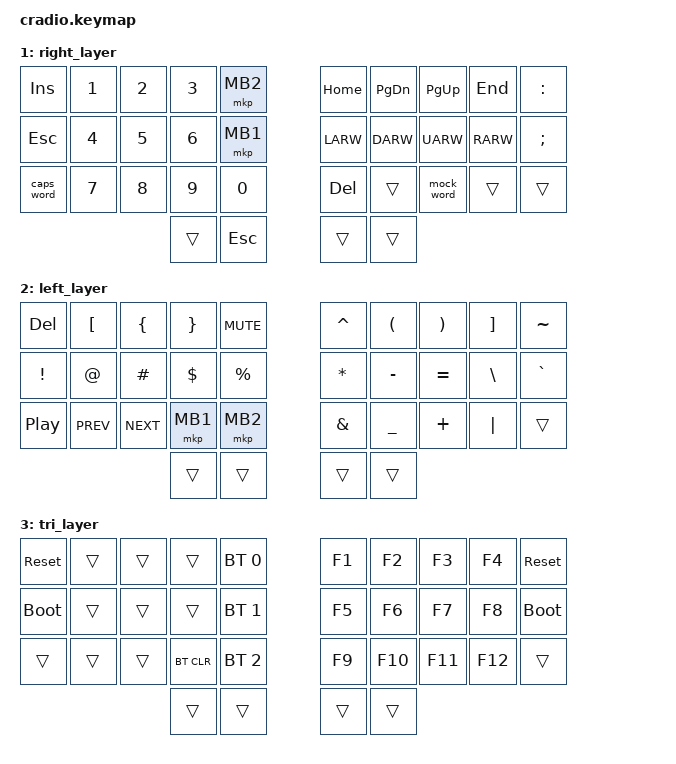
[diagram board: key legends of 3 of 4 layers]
// Copyright (c) 2022 The ZMK Contributors
// SPDX-License-Identifier: MIT

#include <behaviors.dtsi>
#include <dt-bindings/zmk/keys.h>
#include <dt-bindings/zmk/bt.h>
#include <dt-bindings/zmk/pointing.h>

// Home row mods macro
#define HRML(k1,k2,k3,k4) &ht LGUI k1  &ht LALT k2  &ht LCTRL k3  &ht LSHFT k4
#define HRMR(k1,k2,k3,k4) &ht RSHFT k1  &ht RCTRL k2  &ht RALT k3  &ht RGUI k4

// Combo macro
#define COMBO(NAME, BINDINGS, KEYPOS) \
  combo_##NAME { \
    timeout-ms = <50>; \
    require-prior-idle-ms = <150>; \
    bindings = <BINDINGS>; \
    key-positions = <KEYPOS>; \
    layers = <0>; \
  };

/ {
      combos {
        compatible = "zmk,combos";
        COMBO(Z, &kp Z, 0 1)
        COMBO(Q, &kp Q, 1 2)
        COMBO(capsword, &caps_word, 1 3)

        COMBO(tmux, &kp LC(B), 11 13)
        COMBO(tmux2, &kp LC(B), 16 18)
        COMBO(copy, &kp LG(C), 21 22)
        COMBO(paste, &kp LG(V), 20 21)
        COMBO(undo, &kp LG(Z), 26 27)
        COMBO(cut, &kp LG(X), 27 28)
        COMBO(backslash, &kp BSLH, 28 29)
        COMBO(bspc, &kp BSPC, 26 28)

        COMBO(esckey, &kp ESC, 2 3)
        COMBO(esckey2, &kp ESC, 6 7)
        COMBO(tabkey, &kp TAB, 12 13)
        COMBO(tabkey2, &kp TAB, 16 17)
        COMBO(space, &kp SPACE, 22 23)
        COMBO(enter, &kp RET, 21 23)
        
        COMBO(one, &kp LC(N1), 0 10)
        COMBO(two, &kp LC(N2), 1 11)
        COMBO(three, &kp LC(N3), 2 12)
        COMBO(four, &kp LC(N4), 3 13)
        COMBO(five, &kp LC(N5), 4 14)
        COMBO(six, &kp LC(N6), 5 15)
        COMBO(seven, &kp LC(N7), 6 16)
        COMBO(eight, &kp LC(N8), 7 17)
        COMBO(nine, &kp LC(N9), 8 18)
        COMBO(zero, &kp LC(N0), 9 19)

        // COMBO(ctrlL, &kp LC(LEFT), 10 11)
        // COMBO(ctrlR, &kp LC(RIGHT), 11 12)
        // COMBO(ctrl1, &kp LC(N1), 4 5)
        // COMBO(ctrl2, &kp LC(N2), 14 15)
        // COMBO(ctrl3, &kp LC(N3), 24 25)
        // COMBO(ctrl4, &kp LC(N4), 6 7)
        // COMBO(ctrl5, &kp LC(N5), 16 17)
        // COMBO(ctrl6, &kp LC(N6), 26 27)

    };

    behaviors {
        ht: hold_tap {
            label = "hold_tap";
            compatible = "zmk,behavior-hold-tap";
            #binding-cells = <2>;
            flavor = "tap-preferred";
            tapping-term-ms = <220>;
            quick-tap-ms = <150>;
            global-quick-tap;
            bindings = <&kp>, <&kp>;
        };

        // SpongeBob random-caps mode. Toggle on, type, toggle off. SPACE is in
        // the continue-list so it mocks whole sentences; ends on enter/punct.
        mock_word: mock_word {
            compatible = "zmk,behavior-mock-word";
            #binding-cells = <0>;
            continue-list = <UNDERSCORE BACKSPACE DELETE MINUS SPACE>;
        };
    };

    conditional_layers {
        compatible = "zmk,conditional-layers";
        tri_layer {
            if-layers = <1 2>;
            then-layer = <3>;
        };
    };



    keymap {
        compatible = "zmk,keymap";
        default_layer {
            bindings = <
        //╭──────────┬──────────┬──────────┬──────────┬──────────╮   ╭──────────┬──────────┬──────────┬──────────┬──────────╮
        //│  X       │  W       │  M       │  G       │  J       │   │  \       │  .       │  /       │  '       │  `       │
            &kp X      &kp W      &kp M      &kp G      &kp J          &kp BSLH   &kp DOT    &kp FSLH   &kp SQT    &kp GRAVE
        //├──────────┼──────────┼──────────┼──────────┼──────────┤   ├──────────┼──────────┼──────────┼──────────┼──────────┤
        //│  S       │  C       │  N       │  T       │  K       │   │  ,       │  A       │  E       │  I       │   H      │
            HRML(S,     C,         N,         T)     &kp K          &kp COMMA  HRMR(A,         E,        I,          H)
        //├──────────┼──────────┼──────────┼──────────┼──────────┤   ├──────────┼──────────┼──────────┼──────────┼──────────┤
        //│  F       │  P       │  L       │  D       │  V       │   │  -       │  U       │  O       │    Y     │   B      │
            &kp F      &kp P      &kp L      &kp D      &kp V          &kp MINUS  &kp U      &kp O        &kp Y      &kp B
        //╰──────────┴──────────┴──────────┼──────────┼──────────┤   ├──────────┼──────────┼──────────┴──────────┴──────────╯
                                            &lt 2 C_VOL_DN &lt 2 R      &lt 1 SPACE  &lt 1 C_VOL_UP
        //                                 ╰──────────┴──────────╯   ╰──────────┴──────────╯
            >;
        };

        right_layer {
            bindings = <
        //╭──────────┬──────────┬──────────┬──────────┬──────────╮   ╭──────────┬──────────┬──────────┬──────────┬──────────╮
        //│ INSERT   │  1       │  2       │  3       │          │   │ HOME     │ PAGE DN  │ PAGE UP  │ END      │  :       │
            &kp INS    &kp N1     &kp N2     &kp N3     &mkp MB2       &kp HOME   &kp PG_DN  &kp PG_UP  &kp END    &kp COLON
        //├──────────┼──────────┼──────────┼──────────┼──────────┤   ├──────────┼──────────┼──────────┼──────────┼──────────┤
        //│ ESC      │  4       │  5       │  6       │          │   │ LEFT     │ DOWN     │ UP       │ RIGHT    │  ;       │
            &kp ESC    &kp N4     &kp N5     &kp N6     &mkp MB1       &kp LARW   &kp DARW   &kp UARW   &kp RARW   &kp SEMI
        //├──────────┼──────────┼──────────┼──────────┼──────────┤   ├──────────┼──────────┼──────────┼──────────┼──────────┤
        //│ CAPS     │  7       │  8       │  9       │  0       │   │ DEL      │          │ MOCK     │          │          │
           &caps_word  &kp N7     &kp N8     &kp N9     &kp N0         &kp DEL    &trans   &mock_word   &trans     &trans
        //╰──────────┴──────────┴──────────┼──────────┼──────────┤   ├──────────┼──────────┼──────────┴──────────┴──────────╯
                                             &trans     &kp ESC        &trans     &trans
        //                                 ╰──────────┴──────────╯   ╰──────────┴──────────╯
            >;
        };

        left_layer {
            bindings = <
        //╭──────────┬──────────┬──────────┬──────────┬──────────╮   ╭──────────┬──────────┬──────────┬──────────┬──────────╮
        //│ DEL      │  [       │  {       │  }       │  MUTE    │   │  ^       │  (       │  )       │  ]       │  ~       │
            &kp DEL    &kp LBKT  &kp LBRC  &kp RBRC   &kp C_MUTE     &kp CARET  &kp LPAR   &kp RPAR   &kp RBKT   &kp TILDE
        //├──────────┼──────────┼──────────┼──────────┼──────────┤   ├──────────┼──────────┼──────────┼──────────┼──────────┤
        //│  !       │  @       │  #       │  $       │  %       │   │  *       │  -       │  =       │  \       │  `       │
            &kp EXCL   &kp AT     &kp HASH   &kp DLLR   &kp PRCNT      &kp ASTRK  &kp MINUS  &kp EQUAL  &kp BSLH   &kp GRAVE
        //├──────────┼──────────┼──────────┼──────────┼──────────┤   ├──────────┼──────────┼──────────┼──────────┼──────────┤
        //│          │          │          │          │          │   │  &       │  _       │  +       │  │       │          │
         &kp C_PP &kp C_PREV   &kp C_NEXT &mkp MB1      &mkp MB2       &kp AMPS   &kp UNDER  &kp PLUS   &kp PIPE   &trans
        //╰──────────┴──────────┴──────────┼──────────┼──────────┤   ├──────────┼──────────┼──────────┴──────────┴──────────╯
                                             &trans     &trans         &trans     &trans
        //                                 ╰──────────┴──────────╯   ╰──────────┴──────────╯
            >;
        };

        tri_layer {
            bindings = <
        //╭──────────┬──────────┬──────────┬──────────┬──────────╮   ╭──────────┬──────────┬──────────┬──────────┬──────────╮
        //│ RESET    │          │          │          │PROFILE 0 │   │  F1      │  F2      │  F3      │  F4      │  RESET   │
           &sys_reset  &trans     &trans     &trans    &bt BT_SEL 0    &kp F1     &kp F2     &kp F3     &kp F4    &sys_reset
        //├──────────┼──────────┼──────────┼──────────┼──────────┤   ├──────────┼──────────┼──────────┼──────────┼──────────┤
        //│BOOTLOADER│          │          │          │PROFILE 1 │   │  F5      │  F6      │  F7      │  F8      │BOOTLOADER│
          &bootloader  &trans     &trans     &trans    &bt BT_SEL 1    &kp F5     &kp F6     &kp F7     &kp F8    &bootloader
        //├──────────┼──────────┼──────────┼──────────┼──────────┤   ├──────────┼──────────┼──────────┼──────────┼──────────┤
        //│          │          │          │ CLEAR BT │PROFILE 2 │   │  F9      │  F10     │  F11     │  F12     │          │
            &trans     &trans     &trans    &bt BT_CLR &bt BT_SEL 2    &kp F9     &kp F10    &kp F11    &kp F12    &trans
        //╰──────────┴──────────┴──────────┼──────────┼──────────┤   ├──────────┼──────────┼──────────┴──────────┴──────────╯
                                             &trans     &trans         &trans     &trans
        //                                 ╰──────────┴──────────╯   ╰──────────┴──────────╯
            >;
        };
    };
};

